# f28004x_cla_regs register map
Vendor: Texas Instruments
Peripheral module from a debugger description file (folder C2000).
Address unit: 16 bits
Registers are 16-bit, read-write, no defined reset value unless marked. A register's access mark holds for its fields unless they carry their own. Offsets are as the file gives them; lines under a group give offsets from that group; [hi:lo] are bit positions; {n}, {i} and the like mark numbered series; 'fields as' and 'values as' point back to an identical list; <NAME> marks a mode.

## CLA_REGS — CLA Registers
0x00 MVECT1 — Task Interrupt Vector
  [15:0] MVECT — Offset of the first instruction
0x01 MVECT2 — Task Interrupt Vector
  [15:0] MVECT — Offset of the first instruction
0x02 MVECT3 — Task Interrupt Vector
  [15:0] MVECT — Offset of the first instruction
0x03 MVECT4 — Task Interrupt Vector
  [15:0] MVECT — Offset of the first instruction
0x04 MVECT5 — Task Interrupt Vector
  [15:0] MVECT — Offset of the first instruction
0x05 MVECT6 — Task Interrupt Vector
  [15:0] MVECT — Offset of the first instruction
0x06 MVECT7 — Task Interrupt Vector
  [15:0] MVECT — Offset of the first instruction
0x07 MVECT8 — Task Interrupt Vector
  [15:0] MVECT — Offset of the first instruction
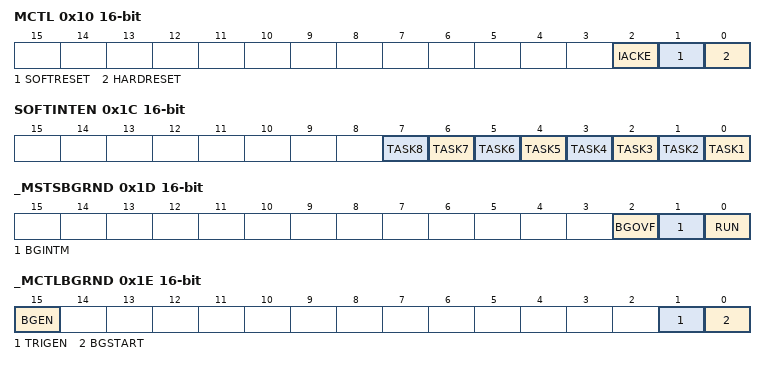
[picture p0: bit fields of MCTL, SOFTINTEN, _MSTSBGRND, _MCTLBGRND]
0x10 MCTL access not given — Control Register
  [2] IACKE rw — IACK enable
  [1] SOFTRESET — Soft Reset (access R=0/W=1)
  [0] HARDRESET — Hard Reset (access R=0/W=1)
0x1B _MVECTBGRNDACTIVE ro — Active register for MVECTBGRND.
  [15:0] i16 — Active register for the Background Task Vector
0x1C SOFTINTEN — CLA Software Interrupt Enable Register
  [n-1] TASK{n} (n=1..8) — Configure Software Interrupt or End of Task interrupt.
0x1D _MSTSBGRND access not given — Status register for the back ground task.
  [2] BGOVF — background task harware trigger overflow. (access R/W1toClr)
  [1] BGINTM ro — Indicates whether background task can be interrupted.
  [0] RUN ro — Background task run status bit.
0x1E _MCTLBGRND access not given — Control register for the back ground task.
  [15] BGEN rw — Enable background task
  [1] TRIGEN rw — Background task hardware trigger enable
  [0] BGSTART — Background task start bit (access R/W=1)
0x1F _MVECTBGRND — Vector for the back ground task.
  [15:0] i16 — Background task vector
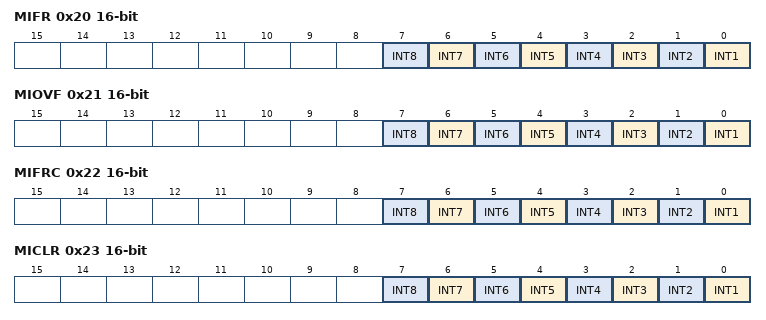
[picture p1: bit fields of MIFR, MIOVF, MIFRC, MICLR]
0x20 MIFR ro — Interrupt Flag Register
  [n-1] INT{n} (n=1..8) — Task {n} Interrupt Flag
0x21 MIOVF ro — Interrupt Overflow Flag Register
  [n-1] INT{n} (n=1..8) — Task {n} Interrupt Overflow Flag
0x22 MIFRC access not given — Interrupt Force Register
  [n-1] INT{n} (n=1..8) — Task {n} Interrupt Force (access R=0/W=1)
0x23 MICLR access not given — Interrupt Flag Clear Register
  [n-1] INT{n} (n=1..8) — Task {n} Interrupt Flag Clear (access R=0/W=1)
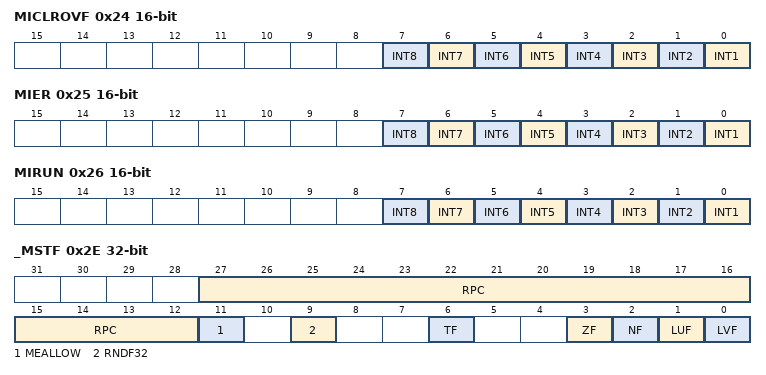
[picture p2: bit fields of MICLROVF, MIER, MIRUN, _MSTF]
0x24 MICLROVF access not given — Interrupt Overflow Flag Clear Register
  [n-1] INT{n} (n=1..8) — Task {n} Interrupt Overflow Flag Clear (access R=0/W=1)
0x25 MIER — Interrupt Enable Register
  [n-1] INT{n} (n=1..8) — Task {n} Interrupt Enable
0x26 MIRUN ro — Interrupt Run Status Register
  [n-1] INT{n} (n=1..8) — Task {n} Run Status
0x28 _MPC ro — CLA Program Counter
  [15:0] _MPC — Points to the instruction
0x2A _MAR0 ro — CLA Auxiliary Register 0
  [15:0] _MAR0 — CLA Auxillary Register 0
0x2B _MAR1 ro — CLA Auxiliary Register 1
  [15:0] _MAR1 — CLA Auxillary Register 1
0x2E _MSTF 32-bit ro — CLA Floating-Point Status Register
  [27:12] RPC — Return PC
  [11] MEALLOW — MEALLOW Status
  [9] RNDF32 — Round 32-bit Floating-Point Mode
  [6] TF — Test Flag
  [3] ZF — Zero Float Flag
  [2] NF — Negative Float Flag
  [1] LUF — Latched Underflow Flag
  [0] LVF — Latched Overflow Flag
{0x30+4i} _MR{i} 32-bit ro (i=0..3) — CLA Floating-Point Result Register {i}
  [31:0] i32 — CLA Result Register {i}
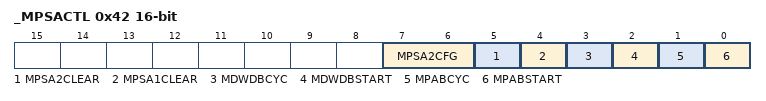
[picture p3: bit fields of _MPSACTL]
0x42 _MPSACTL access not given — CLA PSA Control Register
  [7:6] MPSA2CFG rw — PSA2 Polynomial Configuration
  [5] MPSA2CLEAR — PSA2 Clear (access R=0/W=1)
  [4] MPSA1CLEAR — PSA1 clear (access R=0/W=1)
  [3] MDWDBCYC rw — DWDB logging into PSA2 is on every cycle.
  [2] MDWDBSTART rw — Start logging DWDB onto PSA2
  [1] MPABCYC rw — PAB logging into PSA1 is on every cycle or when PAB changes.
  [0] MPABSTART rw — Start logging PAB onto PSA1
0x44 _MPSA1 32-bit — CLA PSA1 Register
  [31:0] i32 — PSA1
0x46 _MPSA2 32-bit — CLA PSA2 Register
  [31:0] i32 — PSA2
